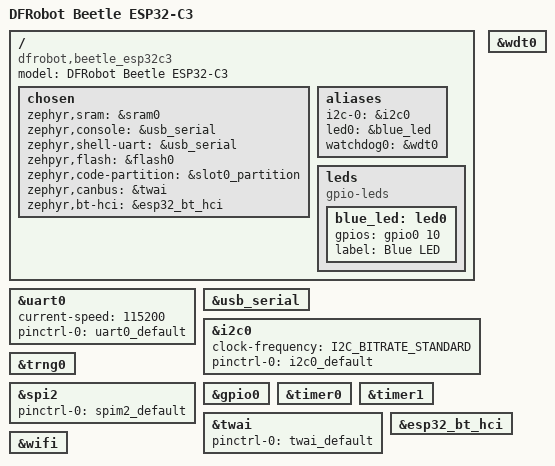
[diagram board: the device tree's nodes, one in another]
/*
 * Copyright (c) 2025 Mikołaj Rosowski
 *
 * SPDX-License-Identifier: Apache-2.0
 */

/dts-v1/;

#include <espressif/esp32c3/esp32c3_fx4.dtsi>
#include <espressif/partitions_0x0_default.dtsi>
#include <zephyr/dt-bindings/gpio/gpio.h>
#include <zephyr/dt-bindings/i2c/i2c.h>
#include <zephyr/dt-bindings/pwm/pwm.h>
#include "beetle_esp32c3-pinctrl.dtsi"

/ {
	model = "DFRobot Beetle ESP32-C3";
	compatible = "dfrobot,beetle_esp32c3";

	chosen {
		zephyr,sram = &sram0;
		zephyr,console = &usb_serial;
		zephyr,shell-uart = &usb_serial;
		zehpyr,flash = &flash0;
		zephyr,code-partition = &slot0_partition;
		zephyr,canbus = &twai;
		zephyr,bt-hci = &esp32_bt_hci;
	};

	aliases {
		i2c-0 = &i2c0;
		led0 = &blue_led;
		watchdog0 = &wdt0;
	};

	leds {
		compatible = "gpio-leds";

		blue_led: led0 {
			gpios = <&gpio0 10 GPIO_ACTIVE_HIGH>;
			label = "Blue LED";
		};
	};
};

&uart0 {
	status = "okay";
	current-speed = <115200>;
	pinctrl-0 = <&uart0_default>;
	pinctrl-names = "default";
};

&usb_serial {
	status = "okay";
};

&i2c0 {
	status = "okay";
	clock-frequency = <I2C_BITRATE_STANDARD>;
	pinctrl-0 = <&i2c0_default>;
	pinctrl-names = "default";
};

&trng0 {
	status = "okay";
};

&spi2 {
	#address-cells = <1>;
	#size-cells = <0>;
	status = "okay";
	pinctrl-0 = <&spim2_default>;
	pinctrl-names = "default";
};

&gpio0 {
	status = "okay";
};

&wdt0 {
	status = "okay";
};

&timer0 {
	status = "okay";
};

&timer1 {
	status = "okay";
};

&twai {
	status = "okay";
	pinctrl-0 = <&twai_default>;
	pinctrl-names = "default";
};

&esp32_bt_hci {
	status = "okay";
};

&wifi {
	status = "okay";
};
